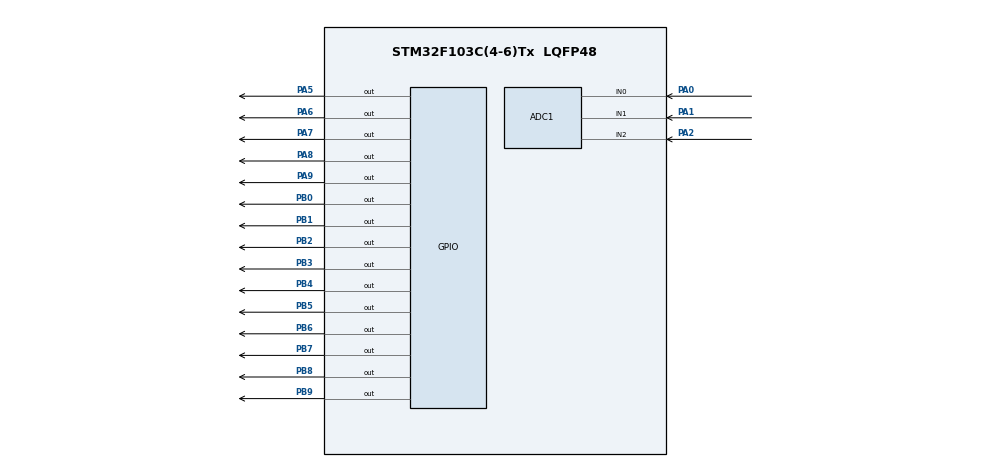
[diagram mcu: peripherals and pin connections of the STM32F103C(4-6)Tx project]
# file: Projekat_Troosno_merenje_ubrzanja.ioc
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ADC1.Channel-0\#ChannelRegularConversion=ADC_CHANNEL_0
ADC1.NbrOfConversionFlag=1
ADC1.Rank-0\#ChannelRegularConversion=1
ADC1.SamplingTime-0\#ChannelRegularConversion=ADC_SAMPLETIME_1CYCLE_5
ADC1.master=1
Mcu.Family=STM32F1
Mcu.Name=STM32F103C(4-6)Tx
Mcu.Package=LQFP48
NVIC.PriorityGroup=NVIC_PRIORITYGROUP_4
PA0-WKUP.Signal=ADCx_IN0
PA1.Signal=ADCx_IN1
PA2.Signal=ADCx_IN2
PA5.Signal=GPIO_Output
PA6.Signal=GPIO_Output
PA7.Signal=GPIO_Output
PA8.Signal=GPIO_Output
PA9.Signal=GPIO_Output
PB0.Signal=GPIO_Output
PB1.Signal=GPIO_Output
PB2.Signal=GPIO_Output
PB3.Signal=GPIO_Output
PB4.Signal=GPIO_Output
PB5.Signal=GPIO_Output
PB6.Signal=GPIO_Output
PB7.Signal=GPIO_Output
PB8.Signal=GPIO_Output
PB9.Signal=GPIO_Output
PD0-OSC_IN.Mode=HSE-External-Oscillator
PD0-OSC_IN.Signal=RCC_OSC_IN
PD1-OSC_OUT.Mode=HSE-External-Oscillator
PD1-OSC_OUT.Signal=RCC_OSC_OUT
ProjectManager.HeapSize=0x200
ProjectManager.StackSize=0x400
ProjectManager.TargetToolchain=STM32CubeIDE
RCC.APB1Freq_Value=8000000
RCC.APB2Freq_Value=8000000
SH.ADCx_IN0.0=ADC1_IN0,IN0
SH.ADCx_IN1.0=ADC1_IN1,IN1
SH.ADCx_IN2.0=ADC1_IN2,IN2
VP_SYS_VS_ND.Mode=No_Debug
board=custom

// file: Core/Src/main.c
/* USER CODE BEGIN Header */
/**
  ******************************************************************************
  * @file           : main.c
  * @brief          : Main program body
  ******************************************************************************
  * @attention
  *
  * <h2><center>&copy; Copyright (c) 2022 STMicroelectronics.
  * All rights reserved.</center></h2>
  *
  * This software component is licensed by ST under BSD 3-Clause license,
  * the "License"; You may not use this file except in compliance with the
  * License. You may obtain a copy of the License at:
  *                        opensource.org/licenses/BSD-3-Clause
  *
  ******************************************************************************
  */
/* USER CODE END Header */

#include "main.h"
#include "math.h"

ADC_HandleTypeDef hadc1;

void SystemClock_Config(void);
static void MX_GPIO_Init(void);
static void MX_ADC1_Init(void);

void LCD_init()
{
	LCD(0x38, 0); //2 lines, 5*7 matrix
	LCD(0x0C, 0); //Display on, cursor off
	LCD(0x06, 0); //Increment cursor (shift to right)
	LCD(0x01, 0); //Clear display screen
	LCD(0x80, 0); //Forse cursos to beginning (1st line)
}

void LCD(uint8_t val_1, uint8_t cmd)
{
	uint8_t data1;

	HAL_GPIO_WritePin(GPIOB, GPIO_PIN_8, cmd);

	data1 = val_1 & 0x01;
	HAL_GPIO_WritePin(GPIOB, GPIO_PIN_0, data1);

	data1 = (val_1 >> 1) & 0x01;
	HAL_GPIO_WritePin(GPIOB, GPIO_PIN_1, data1);

	data1 = (val_1 >> 2) & 0x01;
	HAL_GPIO_WritePin(GPIOB, GPIO_PIN_2, data1);

	data1 = (val_1 >> 3) & 0x01;
	HAL_GPIO_WritePin(GPIOB, GPIO_PIN_3, data1);

	data1 = (val_1 >> 4) & 0x01;
	HAL_GPIO_WritePin(GPIOB, GPIO_PIN_4, data1);

	data1 = (val_1 >> 5) & 0x01;
	HAL_GPIO_WritePin(GPIOB, GPIO_PIN_5, data1);

	data1 = (val_1 >> 6) & 0x01;
	HAL_GPIO_WritePin(GPIOB, GPIO_PIN_6, data1);

	data1 = (val_1 >> 7) & 0x01;
	HAL_GPIO_WritePin(GPIOB, GPIO_PIN_7, data1);

	HAL_GPIO_WritePin(GPIOB, GPIO_PIN_9, GPIO_PIN_SET);
	HAL_Delay(5);
	HAL_GPIO_WritePin(GPIOB, GPIO_PIN_9, GPIO_PIN_RESET);

}

void ispis_broja(float broj)
{
	int ceo;
    float ost;
    int ostCeo=0;
    int i=0;
    char buffer[10];

    ceo = broj;
    ost = broj-ceo;

    ostCeo = ost*1000000;
    ostCeo=abs(ostCeo);
    sprintf(buffer,"%d",ceo);
	while(buffer[i])
	{
		LCD(buffer[i],1);
		i++;
	}

	LCD('.',1);
	sprintf(buffer,"%d",ostCeo);
	i=0;

	while(buffer[i])
	{
		LCD(buffer[i],1);
		i++;
	}
}

void lcd_puts(const char * s)
{
	while(*s)
	LCD(*s++,1);
}

int main(void)
{

  /* MCU Configuration--------------------------------------------------------*/

  /* Reset of all peripherals, Initializes the Flash interface and the Systick. */
  HAL_Init();

  /* Configure the system clock */
  SystemClock_Config();

  /* Initialize all configured peripherals */
  MX_GPIO_Init();
  MX_ADC1_Init();

  /* Infinite loop */
  /* USER CODE BEGIN WHILE */
  uint16_t vrednost;

  //ubrzanja za ose
  float aX;
  float aY;
  float aZ;

  float res;
  HAL_GPIO_WritePin(GPIOA, GPIO_PIN_5, GPIO_PIN_RESET);
  HAL_GPIO_WritePin(GPIOA, GPIO_PIN_6, GPIO_PIN_RESET);
  HAL_GPIO_WritePin(GPIOA, GPIO_PIN_7, GPIO_PIN_RESET);
  HAL_GPIO_WritePin(GPIOA, GPIO_PIN_8, GPIO_PIN_RESET);
  HAL_GPIO_WritePin(GPIOA, GPIO_PIN_9, GPIO_PIN_RESET);
  while (1)
  {

    /* USER CODE END WHILE */

	  HAL_GPIO_WritePin(GPIOA, GPIO_PIN_9, GPIO_PIN_SET);
	  LCD_init();
	  lcd_puts("POCINJE_RACUNANJE");

	  HAL_Delay(300);
	  HAL_GPIO_WritePin(GPIOA, GPIO_PIN_9, GPIO_PIN_RESET);

	  HAL_GPIO_WritePin(GPIOA, GPIO_PIN_8, GPIO_PIN_SET);
	  HAL_ADC_Start(&hadc1);
	  HAL_ADC_PollForConversion(&hadc1, 1000);
	  vrednost=HAL_ADC_GetValue(&hadc1);
	  aX=(vrednost*3.3)/4096+6.1;

	  LCD_init();
	  lcd_puts("X:");

	  ispis_broja(aX);
	  HAL_Delay(300);
	  HAL_GPIO_WritePin(GPIOA, GPIO_PIN_8, GPIO_PIN_RESET);

	  HAL_GPIO_WritePin(GPIOA, GPIO_PIN_7, GPIO_PIN_SET);
	  HAL_ADC_PollForConversion(&hadc1, 1000);
	  vrednost=HAL_ADC_GetValue(&hadc1);
	  aY=(vrednost*3.3)/4096+0.5;

	  LCD_init();
	  lcd_puts("Y:");

	  ispis_broja(aY);
	  HAL_Delay(300);
	  HAL_GPIO_WritePin(GPIOA, GPIO_PIN_7, GPIO_PIN_RESET);

	  HAL_GPIO_WritePin(GPIOA, GPIO_PIN_6, GPIO_PIN_SET);
	  HAL_ADC_PollForConversion(&hadc1, 1000);
	  vrednost=HAL_ADC_GetValue(&hadc1);
	  aZ=(vrednost*3.3)/4096+2.7;

	  LCD_init();
	  lcd_puts("Z:");

	  ispis_broja(aZ);
	  HAL_Delay(300);
	  HAL_GPIO_WritePin(GPIOA, GPIO_PIN_6, GPIO_PIN_RESET);

	  HAL_GPIO_WritePin(GPIOA, GPIO_PIN_5, GPIO_PIN_SET);
	  res=sqrt(aX*aX+aY*aY+aZ*aZ);
	  LCD_init();
	  lcd_puts("UBRZANJE JE:");
	  HAL_Delay(300);

	  LCD_init();
	  ispis_broja(res);
	  lcd_puts("m/s^2");

	  HAL_Delay(300);
	  HAL_GPIO_WritePin(GPIOA, GPIO_PIN_5, GPIO_PIN_RESET);
  }
}

void SystemClock_Config(void)
{
  RCC_OscInitTypeDef RCC_OscInitStruct = {0};
  RCC_ClkInitTypeDef RCC_ClkInitStruct = {0};
  RCC_PeriphCLKInitTypeDef PeriphClkInit = {0};

  /** Initializes the CPU, AHB and APB busses clocks
  */
  RCC_OscInitStruct.OscillatorType = RCC_OSCILLATORTYPE_HSI;
  RCC_OscInitStruct.HSIState = RCC_HSI_ON;
  RCC_OscInitStruct.HSICalibrationValue = RCC_HSICALIBRATION_DEFAULT;
  RCC_OscInitStruct.PLL.PLLState = RCC_PLL_NONE;
  if (HAL_RCC_OscConfig(&RCC_OscInitStruct) != HAL_OK)
  {
    Error_Handler();
  }
  /** Initializes the CPU, AHB and APB busses clocks
  */
  RCC_ClkInitStruct.ClockType = RCC_CLOCKTYPE_HCLK|RCC_CLOCKTYPE_SYSCLK
                              |RCC_CLOCKTYPE_PCLK1|RCC_CLOCKTYPE_PCLK2;
  RCC_ClkInitStruct.SYSCLKSource = RCC_SYSCLKSOURCE_HSI;
  RCC_ClkInitStruct.AHBCLKDivider = RCC_SYSCLK_DIV1;
  RCC_ClkInitStruct.APB1CLKDivider = RCC_HCLK_DIV1;
  RCC_ClkInitStruct.APB2CLKDivider = RCC_HCLK_DIV1;

  if (HAL_RCC_ClockConfig(&RCC_ClkInitStruct, FLASH_LATENCY_0) != HAL_OK)
  {
    Error_Handler();
  }
  PeriphClkInit.PeriphClockSelection = RCC_PERIPHCLK_ADC;
  PeriphClkInit.AdcClockSelection = RCC_ADCPCLK2_DIV2;
  if (HAL_RCCEx_PeriphCLKConfig(&PeriphClkInit) != HAL_OK)
  {
    Error_Handler();
  }
}

static void MX_ADC1_Init(void)
{

  ADC_ChannelConfTypeDef sConfig = {0};

  /** Common config
  */
  hadc1.Instance = ADC1;
  hadc1.Init.ScanConvMode = ADC_SCAN_DISABLE;
  hadc1.Init.ContinuousConvMode = DISABLE;
  hadc1.Init.DiscontinuousConvMode = DISABLE;
  hadc1.Init.ExternalTrigConv = ADC_SOFTWARE_START;
  hadc1.Init.DataAlign = ADC_DATAALIGN_RIGHT;
  hadc1.Init.NbrOfConversion = 1;
  if (HAL_ADC_Init(&hadc1) != HAL_OK)
  {
    Error_Handler();
  }
  /** Configure Regular Channel
  */
  sConfig.Channel = ADC_CHANNEL_0;
  sConfig.Rank = ADC_REGULAR_RANK_1;
  sConfig.SamplingTime = ADC_SAMPLETIME_1CYCLE_5;
  if (HAL_ADC_ConfigChannel(&hadc1, &sConfig) != HAL_OK)
  {
    Error_Handler();
  }

}

static void MX_GPIO_Init(void)
{
  GPIO_InitTypeDef GPIO_InitStruct = {0};

  /* GPIO Ports Clock Enable */
  __HAL_RCC_GPIOD_CLK_ENABLE();
  __HAL_RCC_GPIOA_CLK_ENABLE();
  __HAL_RCC_GPIOB_CLK_ENABLE();

  /*Configure GPIO pin Output Level */
  HAL_GPIO_WritePin(GPIOA, GPIO_PIN_5|GPIO_PIN_6|GPIO_PIN_7|GPIO_PIN_8
                          |GPIO_PIN_9, GPIO_PIN_RESET);

  /*Configure GPIO pin Output Level */
  HAL_GPIO_WritePin(GPIOB, GPIO_PIN_0|GPIO_PIN_1|GPIO_PIN_2|GPIO_PIN_3
                          |GPIO_PIN_4|GPIO_PIN_5|GPIO_PIN_6|GPIO_PIN_7
                          |GPIO_PIN_8|GPIO_PIN_9, GPIO_PIN_RESET);

  /*Configure GPIO pins : PA5 PA6 PA7 PA8
                           PA9 */
  GPIO_InitStruct.Pin = GPIO_PIN_5|GPIO_PIN_6|GPIO_PIN_7|GPIO_PIN_8
                          |GPIO_PIN_9;
  GPIO_InitStruct.Mode = GPIO_MODE_OUTPUT_PP;
  GPIO_InitStruct.Pull = GPIO_NOPULL;
  GPIO_InitStruct.Speed = GPIO_SPEED_FREQ_LOW;
  HAL_GPIO_Init(GPIOA, &GPIO_InitStruct);

  /*Configure GPIO pins : PB0 PB1 PB2 PB3
                           PB4 PB5 PB6 PB7
                           PB8 PB9 */
  GPIO_InitStruct.Pin = GPIO_PIN_0|GPIO_PIN_1|GPIO_PIN_2|GPIO_PIN_3
                          |GPIO_PIN_4|GPIO_PIN_5|GPIO_PIN_6|GPIO_PIN_7
                          |GPIO_PIN_8|GPIO_PIN_9;
  GPIO_InitStruct.Mode = GPIO_MODE_OUTPUT_PP;
  GPIO_InitStruct.Pull = GPIO_NOPULL;
  GPIO_InitStruct.Speed = GPIO_SPEED_FREQ_LOW;
  HAL_GPIO_Init(GPIOB, &GPIO_InitStruct);

}

void Error_Handler(void)
{
}

/************************ (C) COPYRIGHT STMicroelectronics *****END OF FILE****/
